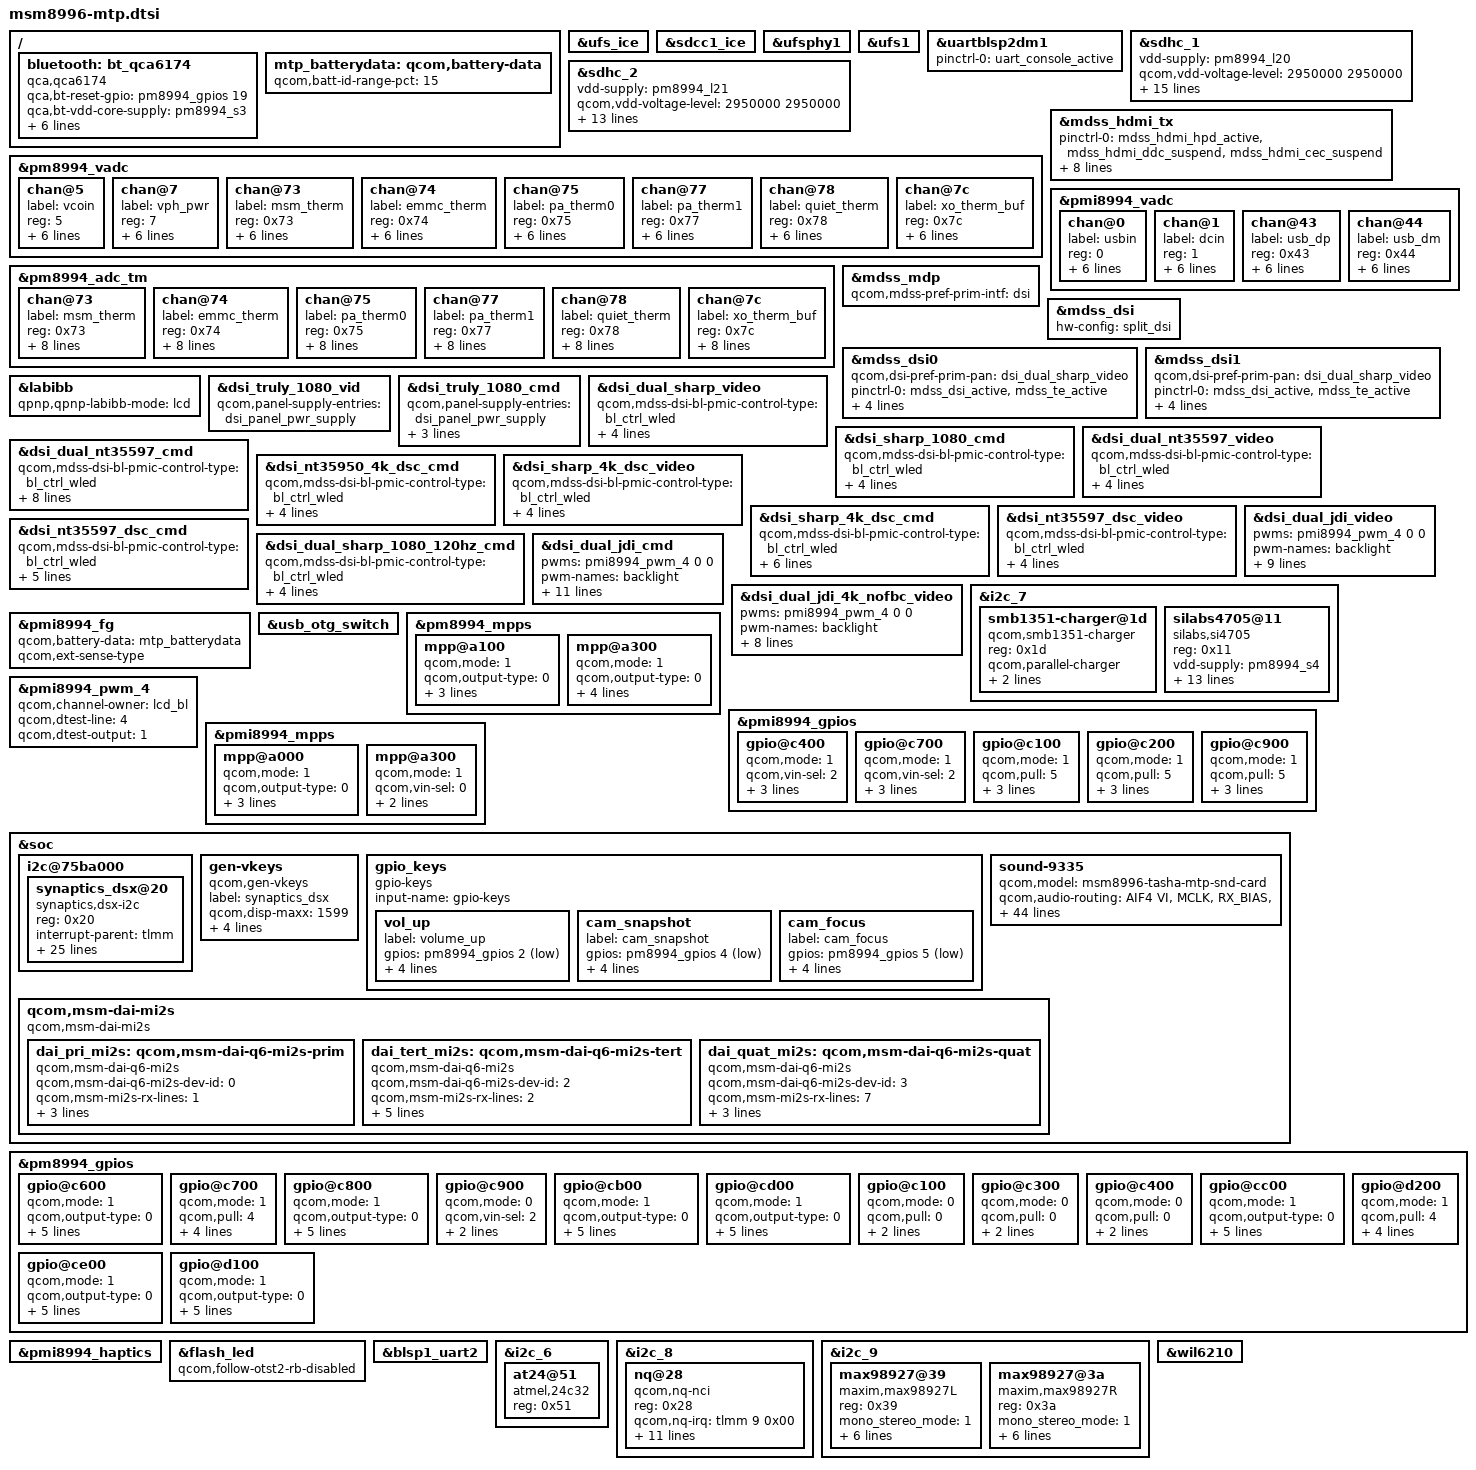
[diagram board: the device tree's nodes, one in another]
/* Copyright (c) 2015-2016, The Linux Foundation. All rights reserved.
 *
 * This program is free software; you can redistribute it and/or modify
 * it under the terms of the GNU General Public License version 2 and
 * only version 2 as published by the Free Software Foundation.
 *
 * This program is distributed in the hope that it will be useful,
 * but WITHOUT ANY WARRANTY; without even the implied warranty of
 * MERCHANTABILITY or FITNESS FOR A PARTICULAR PURPOSE.  See the
 * GNU General Public License for more details.
 */

#include "msm8996-pinctrl.dtsi"
#include "msm8996-camera-sensor-mtp.dtsi"
#include "msm8996-wsa881x.dtsi"

/ {
	bluetooth: bt_qca6174 {
		compatible = "qca,qca6174";
		qca,bt-reset-gpio = <&pm8994_gpios 19 0>; /* BT_EN */
		qca,bt-vdd-core-supply = <&pm8994_s3>;
		qca,bt-vdd-pa-supply = <&rome_vreg>;
		qca,bt-vdd-io-supply = <&pm8994_s4>;
		qca,bt-vdd-xtal-supply = <&pm8994_l30>;
		qca,bt-chip-pwd-voltage-level = <1300000 1300000>;
		qca,bt-vdd-io-voltage-level = <1800000 1800000>;
		qca,bt-vdd-xtal-voltage-level = <1800000 1800000>;
	};
};

&ufs_ice {
        status = "ok";
};

&sdcc1_ice {
        status = "ok";
};

&ufsphy1 {
	status = "ok";
};

&ufs1 {
	status = "ok";
};

&uartblsp2dm1 {
	status = "ok";
	pinctrl-names = "default";
	pinctrl-0 = <&uart_console_active>;
};

&sdhc_1 {
	vdd-supply = <&pm8994_l20>;
	qcom,vdd-voltage-level = <2950000 2950000>;
	qcom,vdd-current-level = <200 570000>;

	vdd-io-supply = <&pm8994_s4>;
	qcom,vdd-io-always-on;
	qcom,vdd-io-voltage-level = <1800000 1800000>;
	qcom,vdd-io-current-level = <110 325000>;

	pinctrl-names = "active", "sleep";
	pinctrl-0 = <&sdc1_clk_on &sdc1_cmd_on &sdc1_data_on &sdc1_rclk_on>;
	pinctrl-1 = <&sdc1_clk_off &sdc1_cmd_off &sdc1_data_off &sdc1_rclk_off>;

	qcom,clk-rates = <400000 20000000 25000000 50000000 96000000 192000000 384000000>;
	qcom,ice-clk-rates = <300000000 150000000>;
	qcom,nonremovable;
	qcom,bus-speed-mode = "HS400_1p8v", "HS200_1p8v", "DDR_1p8v";

	status = "ok";
};

&sdhc_2 {
	vdd-supply = <&pm8994_l21>;
	qcom,vdd-voltage-level = <2950000 2950000>;
	qcom,vdd-current-level = <200 800000>;

	vdd-io-supply = <&pm8994_l13>;
	qcom,vdd-io-voltage-level = <1800000 2950000>;
	qcom,vdd-io-current-level = <200 22000>;

	pinctrl-names = "active", "sleep";
	pinctrl-0 = <&sdc2_clk_on  &sdc2_cmd_on &sdc2_data_on &sdc2_cd_on>;
	pinctrl-1 = <&sdc2_clk_off &sdc2_cmd_off &sdc2_data_off &sdc2_cd_off>;

	qcom,clk-rates = <400000 20000000 25000000 50000000 100000000 200000000>;
	qcom,bus-speed-mode = "SDR12", "SDR25", "SDR50", "DDR50", "SDR104";

	cd-gpios = <&tlmm 95 0x1>;

	status = "ok";
};

&pm8994_vadc {
	chan@5 {
		label = "vcoin";
		reg = <5>;
		qcom,decimation = <0>;
		qcom,pre-div-channel-scaling = <1>;
		qcom,calibration-type = "absolute";
		qcom,scale-function = <0>;
		qcom,hw-settle-time = <0>;
		qcom,fast-avg-setup = <0>;
	};

	chan@7 {
		label = "vph_pwr";
		reg = <7>;
		qcom,decimation = <0>;
		qcom,pre-div-channel-scaling = <1>;
		qcom,calibration-type = "absolute";
		qcom,scale-function = <0>;
		qcom,hw-settle-time = <0>;
		qcom,fast-avg-setup = <0>;
	};

	chan@73 {
		label = "msm_therm";
		reg = <0x73>;
		qcom,decimation = <0>;
		qcom,pre-div-channel-scaling = <0>;
		qcom,calibration-type = "ratiometric";
		qcom,scale-function = <2>;
		qcom,hw-settle-time = <2>;
		qcom,fast-avg-setup = <0>;
	};

	chan@74 {
		label = "emmc_therm";
		reg = <0x74>;
		qcom,decimation = <0>;
		qcom,pre-div-channel-scaling = <0>;
		qcom,calibration-type = "ratiometric";
		qcom,scale-function = <2>;
		qcom,hw-settle-time = <2>;
		qcom,fast-avg-setup = <0>;
	};

	chan@75 {
		label = "pa_therm0";
		reg = <0x75>;
		qcom,decimation = <0>;
		qcom,pre-div-channel-scaling = <0>;
		qcom,calibration-type = "ratiometric";
		qcom,scale-function = <2>;
		qcom,hw-settle-time = <2>;
		qcom,fast-avg-setup = <0>;
	};

	chan@77 {
		label = "pa_therm1";
		reg = <0x77>;
		qcom,decimation = <0>;
		qcom,pre-div-channel-scaling = <0>;
		qcom,calibration-type = "ratiometric";
		qcom,scale-function = <2>;
		qcom,hw-settle-time = <2>;
		qcom,fast-avg-setup = <0>;
	};

	chan@78 {
		label = "quiet_therm";
		reg = <0x78>;
		qcom,decimation = <0>;
		qcom,pre-div-channel-scaling = <0>;
		qcom,calibration-type = "ratiometric";
		qcom,scale-function = <2>;
		qcom,hw-settle-time = <2>;
		qcom,fast-avg-setup = <0>;
	};

	chan@7c {
		label = "xo_therm_buf";
		reg = <0x7c>;
		qcom,decimation = <0>;
		qcom,pre-div-channel-scaling = <0>;
		qcom,calibration-type = "ratiometric";
		qcom,scale-function = <4>;
		qcom,hw-settle-time = <2>;
		qcom,fast-avg-setup = <0>;
	};

	chan@7c {
		label = "xo_therm_buf";
		reg = <0x7c>;
		qcom,decimation = <0>;
		qcom,pre-div-channel-scaling = <0>;
		qcom,calibration-type = "ratiometric";
		qcom,scale-function = <4>;
		qcom,hw-settle-time = <2>;
		qcom,fast-avg-setup = <0>;
	};
};

&pm8994_adc_tm {
	chan@73 {
		label = "msm_therm";
		reg = <0x73>;
		qcom,decimation = <0>;
		qcom,pre-div-channel-scaling = <0>;
		qcom,calibration-type = "ratiometric";
		qcom,scale-function = <2>;
		qcom,hw-settle-time = <2>;
		qcom,fast-avg-setup = <0>;
		qcom,btm-channel-number = <0x48>;
		qcom,thermal-node;
	};

	chan@74 {
		label = "emmc_therm";
		reg = <0x74>;
		qcom,decimation = <0>;
		qcom,pre-div-channel-scaling = <0>;
		qcom,calibration-type = "ratiometric";
		qcom,scale-function = <2>;
		qcom,hw-settle-time = <2>;
		qcom,fast-avg-setup = <0>;
		qcom,btm-channel-number = <0x68>;
		qcom,thermal-node;
	};

	chan@75 {
		label = "pa_therm0";
		reg = <0x75>;
		qcom,decimation = <0>;
		qcom,pre-div-channel-scaling = <0>;
		qcom,calibration-type = "ratiometric";
		qcom,scale-function = <2>;
		qcom,hw-settle-time = <2>;
		qcom,fast-avg-setup = <0>;
		qcom,btm-channel-number = <0x70>;
		qcom,thermal-node;
	};

	chan@77 {
		label = "pa_therm1";
		reg = <0x77>;
		qcom,decimation = <0>;
		qcom,pre-div-channel-scaling = <0>;
		qcom,calibration-type = "ratiometric";
		qcom,scale-function = <2>;
		qcom,hw-settle-time = <2>;
		qcom,fast-avg-setup = <0>;
		qcom,btm-channel-number = <0x78>;
		qcom,thermal-node;
	};

	chan@78 {
		label = "quiet_therm";
		reg = <0x78>;
		qcom,decimation = <0>;
		qcom,pre-div-channel-scaling = <0>;
		qcom,calibration-type = "ratiometric";
		qcom,scale-function = <2>;
		qcom,hw-settle-time = <2>;
		qcom,fast-avg-setup = <0>;
		qcom,btm-channel-number = <0x80>;
		qcom,thermal-node;
	};

	chan@7c {
		label = "xo_therm_buf";
		reg = <0x7c>;
		qcom,decimation = <0>;
		qcom,pre-div-channel-scaling = <0>;
		qcom,calibration-type = "ratiometric";
		qcom,scale-function = <4>;
		qcom,hw-settle-time = <2>;
		qcom,fast-avg-setup = <0>;
		qcom,btm-channel-number = <0x88>;
		qcom,thermal-node;
	};
};

&mdss_hdmi_tx {
	pinctrl-names = "hdmi_hpd_active", "hdmi_ddc_active", "hdmi_cec_active",
				"hdmi_active", "hdmi_sleep";
	pinctrl-0 = <&mdss_hdmi_hpd_active &mdss_hdmi_ddc_suspend
						&mdss_hdmi_cec_suspend>;
	pinctrl-1 = <&mdss_hdmi_hpd_active &mdss_hdmi_ddc_active
						&mdss_hdmi_cec_suspend>;
	pinctrl-2 = <&mdss_hdmi_hpd_active &mdss_hdmi_cec_active
						&mdss_hdmi_ddc_suspend>;
	pinctrl-3 = <&mdss_hdmi_hpd_active &mdss_hdmi_ddc_active
						&mdss_hdmi_cec_active>;
	pinctrl-4 = <&mdss_hdmi_hpd_suspend &mdss_hdmi_ddc_suspend
						&mdss_hdmi_cec_suspend>;
};

&pmi8994_vadc {
	chan@0 {
		label = "usbin";
		reg = <0>;
		qcom,decimation = <0>;
		qcom,pre-div-channel-scaling = <4>;
		qcom,calibration-type = "absolute";
		qcom,scale-function = <0>;
		qcom,hw-settle-time = <0>;
		qcom,fast-avg-setup = <0>;
	};

	chan@1 {
		label = "dcin";
		reg = <1>;
		qcom,decimation = <0>;
		qcom,pre-div-channel-scaling = <4>;
		qcom,calibration-type = "absolute";
		qcom,scale-function = <0>;
		qcom,hw-settle-time = <0>;
		qcom,fast-avg-setup = <0>;
	};

	chan@43 {
		label = "usb_dp";
		reg = <0x43>;
		qcom,decimation = <0>;
		qcom,pre-div-channel-scaling = <1>;
		qcom,calibration-type = "absolute";
		qcom,scale-function = <0>;
		qcom,hw-settle-time = <0>;
		qcom,fast-avg-setup = <0>;
	};

	chan@44 {
		label = "usb_dm";
		reg = <0x44>;
		qcom,decimation = <0>;
		qcom,pre-div-channel-scaling = <1>;
		qcom,calibration-type = "absolute";
		qcom,scale-function = <0>;
		qcom,hw-settle-time = <0>;
		qcom,fast-avg-setup = <0>;
	};
};

#include "msm8996-mdss-panels.dtsi"

&mdss_mdp {
	qcom,mdss-pref-prim-intf = "dsi";
};

&mdss_dsi {
	hw-config = "split_dsi";
};

&mdss_dsi0 {
	qcom,dsi-pref-prim-pan = <&dsi_dual_sharp_video>;
	pinctrl-names = "mdss_default", "mdss_sleep";
	pinctrl-0 = <&mdss_dsi_active &mdss_te_active>;
	pinctrl-1 = <&mdss_dsi_suspend &mdss_te_suspend>;
	qcom,platform-te-gpio = <&tlmm 10 0>;
	qcom,platform-reset-gpio = <&tlmm 8 0>;
	qcom,platform-bklight-en-gpio = <&pm8994_gpios 14 0>;
};

&mdss_dsi1 {
	qcom,dsi-pref-prim-pan = <&dsi_dual_sharp_video>;
	pinctrl-names = "mdss_default", "mdss_sleep";
	pinctrl-0 = <&mdss_dsi_active &mdss_te_active>;
	pinctrl-1 = <&mdss_dsi_suspend &mdss_te_suspend>;
	qcom,platform-te-gpio = <&tlmm 10 0>;
	qcom,platform-reset-gpio = <&tlmm 8 0>;
	qcom,platform-bklight-en-gpio = <&pm8994_gpios 14 0>;
};

&labibb {
	status = "ok";
	qpnp,qpnp-labibb-mode = "lcd";
};

&dsi_truly_1080_vid {
	qcom,panel-supply-entries = <&dsi_panel_pwr_supply>;
};

&dsi_truly_1080_cmd {
	qcom,panel-supply-entries = <&dsi_panel_pwr_supply>;
	qcom,ulps-enabled;
	qcom,partial-update-enabled;
	qcom,panel-roi-alignment = <2 2 4 2 1080 2>;
};

&dsi_dual_sharp_video {
	qcom,mdss-dsi-bl-pmic-control-type = "bl_ctrl_wled";
	qcom,mdss-dsi-bl-min-level = <1>;
	qcom,mdss-dsi-bl-max-level = <4095>;
	qcom,panel-supply-entries = <&dsi_panel_pwr_supply>;
};

&dsi_sharp_1080_cmd {
	qcom,mdss-dsi-bl-pmic-control-type = "bl_ctrl_wled";
	qcom,mdss-dsi-bl-min-level = <1>;
	qcom,mdss-dsi-bl-max-level = <4095>;
	qcom,panel-supply-entries = <&dsi_panel_pwr_supply>;
};

&dsi_dual_nt35597_video {
	qcom,mdss-dsi-bl-pmic-control-type = "bl_ctrl_wled";
	qcom,mdss-dsi-bl-min-level = <1>;
	qcom,mdss-dsi-bl-max-level = <4095>;
	qcom,panel-supply-entries = <&dsi_panel_pwr_supply>;
};

&dsi_dual_nt35597_cmd {
	qcom,mdss-dsi-bl-pmic-control-type = "bl_ctrl_wled";
	qcom,mdss-dsi-bl-min-level = <1>;
	qcom,mdss-dsi-bl-max-level = <4095>;
	qcom,panel-supply-entries = <&dsi_panel_pwr_supply>;
	qcom,partial-update-enabled;
	qcom,panel-roi-alignment = <720 128 720 64 720 64>;
	qcom,panel-allow-phy-poweroff;
};

&dsi_nt35950_4k_dsc_cmd {
	qcom,mdss-dsi-bl-pmic-control-type = "bl_ctrl_wled";
	qcom,mdss-dsi-bl-min-level = <1>;
	qcom,mdss-dsi-bl-max-level = <4095>;
	qcom,panel-supply-entries = <&dsi_panel_pwr_supply>;
};

&dsi_sharp_4k_dsc_video {
	qcom,mdss-dsi-bl-pmic-control-type = "bl_ctrl_wled";
	qcom,mdss-dsi-bl-min-level = <1>;
	qcom,mdss-dsi-bl-max-level = <4095>;
	qcom,panel-supply-entries = <&dsi_panel_pwr_supply>;
};

&dsi_sharp_4k_dsc_cmd {
	qcom,mdss-dsi-bl-pmic-control-type = "bl_ctrl_wled";
	qcom,mdss-dsi-bl-min-level = <1>;
	qcom,mdss-dsi-bl-max-level = <4095>;
	qcom,panel-supply-entries = <&dsi_panel_pwr_supply>;
	qcom,partial-update-enabled;
	/* panel supports slice height of 8/16/32/48/3840 */
	qcom,panel-roi-alignment = <1080 8 1080 8 1080 8>;
};

&dsi_nt35597_dsc_video {
	qcom,mdss-dsi-bl-pmic-control-type = "bl_ctrl_wled";
	qcom,mdss-dsi-bl-min-level = <1>;
	qcom,mdss-dsi-bl-max-level = <4095>;
	qcom,panel-supply-entries = <&dsi_panel_pwr_supply>;
};

&dsi_nt35597_dsc_cmd {
	qcom,mdss-dsi-bl-pmic-control-type = "bl_ctrl_wled";
	qcom,mdss-dsi-bl-min-level = <1>;
	qcom,mdss-dsi-bl-max-level = <4095>;
	qcom,panel-supply-entries = <&dsi_panel_pwr_supply>;
	qcom,panel-allow-phy-poweroff;
};

&dsi_dual_sharp_1080_120hz_cmd {
	qcom,mdss-dsi-bl-pmic-control-type = "bl_ctrl_wled";
	qcom,mdss-dsi-bl-min-level = <1>;
	qcom,mdss-dsi-bl-max-level = <4095>;
	qcom,panel-supply-entries = <&dsi_panel_pwr_supply>;
};

&dsi_dual_jdi_video {
	pwms = <&pmi8994_pwm_4 0 0>;
	pwm-names = "backlight";
	qcom,mdss-dsi-bl-pmic-control-type = "bl_ctrl_pwm";
	qcom,mdss-dsi-bl-pwm-pmi;
	qcom,mdss-dsi-bl-pmic-pwm-frequency = <100>;
	qcom,mdss-dsi-bl-min-level = <1>;
	qcom,mdss-dsi-bl-max-level = <4095>;
	qcom,5v-boost-gpio = <&pmi8994_gpios 8 0>;
	qcom,panel-supply-entries = <&dsi_panel_pwr_supply>;
};

&dsi_dual_jdi_cmd {
	pwms = <&pmi8994_pwm_4 0 0>;
	pwm-names = "backlight";
	qcom,mdss-dsi-bl-pmic-control-type = "bl_ctrl_pwm";
	qcom,mdss-dsi-bl-pwm-pmi;
	qcom,mdss-dsi-bl-pmic-pwm-frequency = <100>;
	qcom,mdss-dsi-bl-min-level = <1>;
	qcom,mdss-dsi-bl-max-level = <4095>;
	qcom,5v-boost-gpio = <&pmi8994_gpios 8 0>;
	qcom,panel-supply-entries = <&dsi_panel_pwr_supply>;
	qcom,partial-update-enabled;
	qcom,panel-roi-alignment = <4 4 2 2 20 20>;
};

&dsi_dual_jdi_4k_nofbc_video {
	pwms = <&pmi8994_pwm_4 0 0>;
	pwm-names = "backlight";
	qcom,mdss-dsi-bl-pmic-control-type = "bl_ctrl_pwm";
	qcom,mdss-dsi-bl-pwm-pmi;
	qcom,mdss-dsi-bl-pmic-pwm-frequency = <100>;
	qcom,mdss-dsi-bl-min-level = <1>;
	qcom,mdss-dsi-bl-max-level = <4095>;
	qcom,panel-supply-entries = <&dsi_panel_pwr_supply>;
};

/{
	mtp_batterydata: qcom,battery-data {
		qcom,batt-id-range-pct = <15>;
		#include "batterydata-zl1-4000mah.dtsi"
	};
};

&i2c_7 {
	smb1351-charger@1d {
		compatible = "qcom,smb1351-charger";
		reg = <0x1d>;
		qcom,parallel-charger;
		qcom,float-voltage-mv = <4400>;
		qcom,recharge-mv = <100>;
	};
};

&pmi8994_fg {
	qcom,battery-data = <&mtp_batterydata>;
	qcom,ext-sense-type;
};

&usb_otg_switch {
	status = "okay";
};

&pm8994_mpps {
	mpp@a100 { /* MPP 2 */
		qcom,mode = <1>;		/* Digital output */
		qcom,output-type = <0>;		/* CMOS logic */
		qcom,vin-sel = <2>;		/* S4 1.8V */
		qcom,src-sel = <0>;		/* Constant */
		qcom,master-en = <1>;		/* Enable GPIO */
		status = "okay";
	};

	mpp@a300 { /* MPP 4 */
		/* HDMI_5v_vreg regulator enable */
		qcom,mode = <1>;		/* Digital output */
		qcom,output-type = <0>;		/* CMOS logic */
		qcom,vin-sel = <2>;		/* S4 1.8V */
		qcom,src-sel = <0>;		/* Constant */
		qcom,master-en = <1>;		/* Enable GPIO */
		qcom,invert = <1>;
		status = "okay";
	};
};

&pmi8994_gpios {
	gpio@c400 { /* GPIO 5 - USB3 OTG SWITCH EN */
		qcom,mode = <1>;	/* Digital output */
		qcom,vin-sel = <2>;	/* 1.8 */
		qcom,src-sel = <0>;	/* GPIO */
		qcom,master-en = <1>;	/* Enable GPIO */
		qcom,invert = <0>;	/* Output low initially */
		status = "okay";
	};
};

&pmi8994_gpios {
	gpio@c700 {	/* GPIO 8, lcd_reg_en, 5V boost  */
		qcom,mode = <1>;
		qcom,vin-sel = <2>;
		qcom,src-sel = <0>;
		qcom,invert = <1>;   /* need invert = 0 */
		qcom,master-en = <1>;
		status = "okay";
	};

	gpio@c100 {	/* GPIO 2  SPKR_SD_N */
		qcom,mode = <1>;	/* DIGITAL OUT */
		qcom,pull = <5>;	/* No Pull */
		qcom,vin-sel = <2>;	/* 1.8 */
		qcom,src-sel = <0>;	/* CONSTANT */
		qcom,master-en = <1>;	/* ENABLE GPIO */
		status = "okay";
	};

	gpio@c200 {	/* GPIO 3 SPKR_SD_N */
		qcom,mode = <1>;	/* DIGITAL OUT */
		qcom,pull = <5>;	/* No Pull */
		qcom,vin-sel = <2>;	/* 1.8 */
		qcom,src-sel = <0>;	/* CONSTANT */
		qcom,master-en = <1>;	/* ENABLE GPIO */
		status = "okay";
	};

	gpio@c900 { /* GPIO 10 - HPH_EN1 */
		qcom,mode = <1>;
		qcom,pull = <5>;
		qcom,vin-sel = <2>;
		qcom,src-sel = <2>;
		qcom,master-en = <1>;
		status = "okay";
	};
};

&pmi8994_pwm_4 {
	qcom,channel-owner = "lcd_bl";
	qcom,dtest-line = <4>;
	qcom,dtest-output = <1>;
	status = "okay";
};

&pmi8994_mpps {
	mpp@a000 { /* MPP 1 */
		qcom,mode = <1>;                /* Digital output */
		qcom,output-type = <0>;         /* CMOS logic */
		qcom,vin-sel = <2>;             /* S4 1.8V */
		qcom,src-sel = <7>;             /* DTEST4 */
		qcom,master-en = <1>;           /* Enable MPP */
		status = "okay";
	};

	mpp@a300 { /* MPP 4 */
		/* WLED FET */
		qcom,mode = <1>;        /* DIGITAL OUT */
		qcom,vin-sel = <0>;     /* VIN0 */
		qcom,src-sel = <1>;
		qcom,master-en = <1>;
		status = "okay";
	};
};

&soc {
	i2c@75ba000 {
		#address-cells = <1>;
		#size-cells = <0>;
		synaptics_dsx@20 {
			compatible = "synaptics,dsx-i2c";
			reg = <0x20>;
			interrupt-parent = <&tlmm>;
			interrupts = <125 0x2008>;
			pinctrl-names = "pmx_ts_active","pmx_ts_suspend";
			pinctrl-0 = <&synaptics_irq_active &synaptics_reset_active>;
			pinctrl-1 = <&synaptics_irq_suspend &synaptics_reset_suspend>;
			vdd_ana-supply = <&pm8994_l22>;
			vcc_i2c-supply = <&pm8994_l14>;
			synaptics,pwr-reg-name = "vdd_ana";
			synaptics,bus-reg-name = "vcc_i2c";
			synaptics,reset-gpio = <&tlmm 89 0x00>;
			synaptics,irq-gpio = <&tlmm 125 0x2008>;
			synaptics,irq-on-state = <0>;
			synaptics,irq-flags = <0x2008>; /* IRQF_ONESHOT | IRQF_TRIGGER_LOW */
			synaptics,power-delay-ms = <200>;
			synaptics,reset-delay-ms = <200>;
			synaptics,reset-on-state = <0>;
			synaptics,reset-active-ms = <20>;
			synaptics,disable-gpios;
			/* Underlying clocks used by secure touch */
			synaptics,cap-button-codes = <580 172 158>;
			synaptics,driver-line-num = <31>;
			synaptics,sense-line-num = <20>;
			synaptics,capacitance-max-value = <
                            2987  2828  2789  2817  2863  2624  2612  2601  2589  2606  2592  2582  2616  2933  2873  2884  3039  0     0     0
                            2960  2805  2766  2793  2838  2600  2589  2577  2567  2583  2568  2558  2591  2909  2850  2861  3012  0     0     0
                            2965  2811  2772  2799  2845  2606  2594  2584  2573  2590  2575  2565  2598  2915  2857  2868  3018  0     0     0
                            2970  2814  2776  2804  2849  2610  2600  2589  2578  2595  2580  2570  2602  2920  2859  2872  3021  0     0     0
                            2975  2818  2779  2808  2854  2615  2603  2594  2582  2599  2584  2574  2608  2925  2865  2876  3025  0     0     0
                            2981  2826  2788  2815  2862  2623  2612  2602  2592  2608  2593  2584  2617  2933  2874  2884  3033  0     0     0
                            2984  2829  2791  2820  2867  2628  2617  2608  2597  2613  2599  2588  2621  2937  2878  2888  3037  0     0     0
                            2990  2836  2798  2827  2874  2634  2624  2614  2605  2620  2606  2597  2630  2945  2885  2895  3044  0     0     0
                            2996  2842  2805  2834  2882  2644  2633  2623  2614  2629  2615  2605  2637  2951  2891  2901  3049  0     0     0
                            3002  2850  2812  2842  2890  2650  2639  2628  2620  2636  2621  2612  2644  2958  2897  2905  3054  0     0     0
                            3010  2857  2819  2849  2899  2657  2648  2638  2628  2643  2629  2620  2651  2964  2902  2913  3059  0     0     0
                            3018  2865  2828  2859  2910  2668  2657  2648  2638  2653  2640  2631  2663  2974  2912  2921  3065  0     0     0
                            3024  2872  2835  2866  2917  2675  2667  2657  2647  2661  2648  2639  2672  2981  2919  2928  3071  0     0     0
                            3034  2881  2845  2876  2928  2686  2676  2668  2660  2674  2659  2651  2683  2991  2928  2936  3078  0     0     0
                            3040  2889  2853  2886  2939  2696  2687  2678  2670  2683  2670  2662  2694  3001  2936  2945  3085  0     0     0
                            3045  2896  2861  2894  2948  2703  2693  2687  2678  2690  2678  2670  2703  3007  2943  2951  3091  0     0     0
                            3052  2904  2869  2903  2958  2712  2703  2697  2688  2702  2686  2679  2713  3016  2951  2959  3097  0     0     0
                            3058  2913  2877  2912  2968  2723  2714  2707  2699  2712  2697  2691  2724  3025  2960  2968  3104  0     0     0
                            3062  2918  2884  2919  2976  2731  2721  2716  2707  2720  2706  2700  2733  3032  2967  2974  3109  0     0     0
                            3071  2928  2896  2931  2989  2742  2734  2729  2721  2732  2720  2714  2746  3043  2978  2984  3118  0     0     0
                            3076  2936  2903  2940  3000  2752  2744  2739  2731  2742  2730  2724  2756  3053  2986  2991  3123  0     0     0
                            3083  2944  2912  2949  3011  2761  2754  2749  2743  2754  2742  2736  2767  3063  2995  3000  3129  0     0     0
                            3087  2949  2918  2955  3018  2769  2760  2757  2749  2760  2748  2744  2775  3068  3001  3006  3134  0     0     0
                            3092  2956  2925  2963  3026  2777  2768  2766  2759  2769  2757  2754  2785  3075  3008  3012  3139  0     0     0
                            3097  2963  2932  2972  3037  2785  2777  2775  2768  2777  2766  2763  2795  3082  3015  3019  3144  0     0     0
                            3103  2971  2943  2982  3048  2794  2787  2786  2779  2787  2777  2774  2806  3090  3023  3028  3150  0     0     0
                            3107  2977  2949  2989  3056  2803  2795  2794  2787  2795  2785  2783  2815  3096  3029  3032  3154  0     0     0
                            3111  2986  2959  2998  3064  2814  2806  2804  2798  2806  2796  2794  2825  3103  3038  3041  3159  0     0     0
                            3120  2996  2970  3010  3077  2827  2819  2819  2814  2821  2810  2807  2839  3113  3049  3051  3168  0     0     0
                            3201  3102  3065  3104  3168  2926  2919  3006  3101  3062  2968  2920  2950  3212  3174  3186  3255  0     0     0
                            0     0     0     0     0     0     0     0     0     0     0     0     0     0     0     0     0     3217  3243  3438>;
			synaptics,capacitance-min-value = <
		                    1992  1886  1859  1878  1909  1749  1741  1734  1726  1737  1728  1721  1744  1955  1915  1923  2026  0     0     0
		                    1974  1870  1844  1862  1892  1733  1726  1718  1711  1722  1712  1705  1727  1939  1900  1907  2008  0     0     0
		                    1977  1874  1848  1866  1897  1737  1729  1723  1715  1726  1717  1710  1732  1944  1905  1912  2012  0     0     0
		                    1980  1876  1851  1869  1900  1740  1733  1726  1719  1730  1720  1713  1734  1947  1906  1915  2014  0     0     0
		                    1983  1879  1853  1872  1902  1743  1735  1729  1722  1733  1723  1716  1739  1950  1910  1917  2017  0     0     0
		                    1988  1884  1858  1877  1908  1749  1741  1735  1728  1739  1729  1722  1744  1955  1916  1923  2022  0     0     0
		                    1989  1886  1860  1880  1911  1752  1745  1738  1731  1742  1732  1725  1748  1958  1918  1925  2025  0     0     0
		                    1993  1891  1865  1885  1916  1756  1749  1743  1736  1747  1737  1731  1753  1963  1923  1930  2029  0     0     0
		                    1997  1895  1870  1889  1921  1762  1755  1749  1743  1753  1743  1737  1758  1968  1927  1934  2033  0     0     0
		                    2002  1900  1874  1894  1926  1767  1759  1752  1747  1757  1748  1741  1763  1972  1931  1937  2036  0     0     0
		                    2007  1905  1879  1899  1933  1772  1765  1758  1752  1762  1753  1747  1768  1976  1935  1942  2039  0     0     0
		                    2012  1910  1886  1906  1940  1779  1771  1766  1759  1769  1760  1754  1775  1983  1941  1947  2044  0     0     0
		                    2016  1914  1890  1911  1944  1783  1778  1771  1765  1774  1766  1760  1781  1987  1946  1952  2047  0     0     0
		                    2022  1921  1896  1918  1952  1791  1784  1779  1773  1782  1773  1767  1789  1994  1952  1958  2052  0     0     0
		                    2026  1926  1902  1924  1960  1797  1791  1786  1780  1789  1780  1775  1796  2001  1958  1963  2057  0     0     0
		                    2030  1931  1907  1930  1965  1802  1795  1791  1785  1794  1785  1780  1802  2005  1962  1968  2060  0     0     0
		                    2035  1936  1912  1935  1972  1808  1802  1798  1792  1801  1791  1786  1809  2011  1968  1973  2065  0     0     0
		                    2038  1942  1918  1942  1979  1815  1809  1805  1799  1808  1798  1794  1816  2017  1973  1979  2069  0     0     0
		                    2042  1945  1923  1946  1984  1821  1814  1810  1805  1813  1804  1800  1822  2021  1978  1982  2073  0     0     0
		                    2047  1952  1931  1954  1993  1828  1823  1819  1814  1822  1813  1809  1831  2029  1985  1989  2078  0     0     0
		                    2051  1957  1935  1960  2000  1835  1829  1826  1820  1828  1820  1816  1837  2035  1991  1994  2082  0     0     0
		                    2055  1962  1942  1966  2007  1841  1836  1833  1828  1836  1828  1824  1845  2042  1997  2000  2086  0     0     0
		                    2058  1966  1945  1970  2012  1846  1840  1838  1833  1840  1832  1829  1850  2045  2001  2004  2090  0     0     0
		                    2061  1971  1950  1975  2017  1851  1845  1844  1839  1846  1838  1836  1857  2050  2006  2008  2093  0     0     0
		                    2064  1975  1955  1981  2025  1857  1851  1850  1845  1852  1844  1842  1863  2054  2010  2013  2096  0     0     0
		                    2068  1981  1962  1988  2032  1863  1858  1857  1853  1858  1851  1850  1871  2060  2016  2018  2100  0     0     0
		                    2071  1985  1966  1993  2037  1869  1864  1863  1858  1864  1857  1855  1876  2064  2020  2022  2102  0     0     0
		                    2074  1990  1972  1999  2042  1876  1871  1869  1866  1871  1864  1862  1883  2069  2025  2027  2106  0     0     0
		                    2080  1998  1980  2006  2051  1884  1879  1879  1876  1880  1873  1871  1893  2076  2033  2034  2112  0     0     0
		                    2134  2068  2043  2069  2112  1951  1946  2004  2067  2042  1979  1947  1967  2141  2116  2124  2170  0     0     0
		                    0     0     0     0     0     0     0     0     0     0     0     0     0     0     0     0     0     1920  1940  2060>;
		};
	};

	gen-vkeys {
		compatible = "qcom,gen-vkeys";
		label = "synaptics_dsx";
		qcom,disp-maxx = <1599>;
		qcom,disp-maxy = <2559>;
		qcom,panel-maxx = <1599>;
		qcom,panel-maxy = <2703>;
		qcom,key-codes = <158 139 102 217>;
	};

	gpio_keys {
		compatible = "gpio-keys";
		input-name = "gpio-keys";

		vol_up {
			label = "volume_up";
			gpios = <&pm8994_gpios 2 0x1>;
			linux,input-type = <1>;
			linux,code = <115>;
			gpio-key,wakeup;
			debounce-interval = <15>;
		};

		cam_snapshot {
			label = "cam_snapshot";
			gpios = <&pm8994_gpios 4 0x1>;
			linux,input-type = <1>;
			linux,code = <766>;
			gpio-key,wakeup;
			debounce-interval = <15>;
		};

		cam_focus {
			label = "cam_focus";
			gpios = <&pm8994_gpios 5 0x1>;
			linux,input-type = <1>;
			linux,code = <528>;
			gpio-key,wakeup;
			debounce-interval = <15>;
		};
	};

	sound-9335 {
		qcom,model = "msm8996-tasha-mtp-snd-card";

		qcom,audio-routing =
			"AIF4 VI", "MCLK",
			"RX_BIAS", "MCLK",
			"MADINPUT", "MCLK",
			"AMIC2", "MIC BIAS2",
			"MIC BIAS2", "Headset Mic",
			"AMIC1", "MIC BIAS1",
			"MIC BIAS1", "Handset Mic",
			"AMIC4", "MIC BIAS4",
			"MIC BIAS4", "REC ANC Analog Mic",
			"AMIC5", "MIC BIAS3",
			"MIC BIAS3", "ANC Analog Mic";

		asoc-platform = <&pcm0>, <&pcm1>, <&pcm2>, <&voip>, <&voice>,
				<&loopback>, <&compress>, <&hostless>,
				<&afe>, <&lsm>, <&routing>, <&cpe>, <&compr>;
		asoc-platform-names = "msm-pcm-dsp.0", "msm-pcm-dsp.1", "msm-pcm-dsp.2",
				"msm-voip-dsp", "msm-pcm-voice", "msm-pcm-loopback",
				"msm-compress-dsp", "msm-pcm-hostless", "msm-pcm-afe",
				"msm-lsm-client", "msm-pcm-routing", "msm-cpe-lsm",
				"msm-compr-dsp";
		asoc-cpu = <&dai_pri_auxpcm>, <&dai_sec_auxpcm>, <&dai_hdmi>,
				<&dai_pri_mi2s>,
				<&dai_tert_mi2s>, <&dai_quat_mi2s>,
				<&sb_0_rx>, <&sb_0_tx>, <&sb_1_rx>, <&sb_1_tx>,
				<&sb_2_rx>, <&sb_2_tx>, <&sb_3_rx>, <&sb_3_tx>,
				<&sb_4_rx>, <&sb_4_tx>, <&sb_5_tx>, <&afe_pcm_rx>,
				<&afe_pcm_tx>, <&afe_proxy_rx>, <&afe_proxy_tx>,
				<&incall_record_rx>, <&incall_record_tx>,
				<&incall_music_rx>, <&incall_music2_rx>,
				<&sb_5_rx>, <&sb_6_rx>;
		asoc-cpu-names = "msm-dai-q6-auxpcm.1", "msm-dai-q6-auxpcm.2",
				"msm-dai-q6-hdmi.8",
				"msm-dai-q6-mi2s.0",
				"msm-dai-q6-mi2s.2", "msm-dai-q6-mi2s.3",
				"msm-dai-q6-dev.16384", "msm-dai-q6-dev.16385",
				"msm-dai-q6-dev.16386", "msm-dai-q6-dev.16387",
				"msm-dai-q6-dev.16388", "msm-dai-q6-dev.16389",
				"msm-dai-q6-dev.16390", "msm-dai-q6-dev.16391",
				"msm-dai-q6-dev.16392", "msm-dai-q6-dev.16393",
				"msm-dai-q6-dev.16395", "msm-dai-q6-dev.224",
				"msm-dai-q6-dev.225", "msm-dai-q6-dev.241",
				"msm-dai-q6-dev.240", "msm-dai-q6-dev.32771",
				"msm-dai-q6-dev.32772", "msm-dai-q6-dev.32773",
				"msm-dai-q6-dev.32770", "msm-dai-q6-dev.16394",
                "msm-dai-q6-dev.16396";

		qcom,hdmi-audio-rx;
		/*letv,hifi-audio;*/
		/*letv,smartpa-audio;*/
		letv,smartpa-audio-max98927;
		letv,hph_irq_detect = <0>;
		asoc-codec = <&stub_codec>, <&hdmi_audio>;
		asoc-codec-names = "msm-stub-codec.1", "msm-hdmi-audio-codec-rx";
		/delete-property/ qcom,hph-en1-gpio;
		/delete-property/ qcom,hph-en0-gpio;
		qcom,us-euro-gpios = <&tlmm 21 0>;
		/delete-property/ qcom,wsa-devs;
		/delete-property/ qcom,wsa-aux-dev-prefix;
	};

	qcom,msm-dai-mi2s {
		compatible = "qcom,msm-dai-mi2s";
		dai_pri_mi2s: qcom,msm-dai-q6-mi2s-prim {
			compatible = "qcom,msm-dai-q6-mi2s";
			qcom,msm-dai-q6-mi2s-dev-id = <0>;
			qcom,msm-mi2s-rx-lines = <1>; /* SD0 (1 << 0) */
			qcom,msm-mi2s-tx-lines = <2>; /* SD1 (1 << 1) */
			qcom,msm-mi2s-slave = <0>;
			qcom,msm-mi2s-ext-mclk = <0>;
		};
	};

	qcom,msm-dai-mi2s {
		compatible = "qcom,msm-dai-mi2s";
		dai_tert_mi2s: qcom,msm-dai-q6-mi2s-tert {
			compatible = "qcom,msm-dai-q6-mi2s";
			qcom,msm-dai-q6-mi2s-dev-id = <2>;
			qcom,msm-mi2s-rx-lines = <2>;
			qcom,msm-mi2s-tx-lines = <1>;
			pinctrl-names = "default", "sleep";
			pinctrl-0 = <&tert_mi2s_active &tert_mi2s_sd0_active &tert_mi2s_sd1_active>;
			pinctrl-1 = <&tert_mi2s_sleep &tert_mi2s_sd0_sleep &tert_mi2s_sd1_sleep>;
		};
	};

	qcom,msm-dai-mi2s {
		compatible = "qcom,msm-dai-mi2s";
		dai_quat_mi2s: qcom,msm-dai-q6-mi2s-quat {
			compatible = "qcom,msm-dai-q6-mi2s";
			qcom,msm-dai-q6-mi2s-dev-id = <3>;
			qcom,msm-mi2s-rx-lines = <7>; /* SD0 (1 << 0) | SD1 (1 << 1) | SD2 (1 << 2) */
			qcom,msm-mi2s-tx-lines = <8>; /* SD2 (1 << 3) */
			qcom,msm-mi2s-slave = <0>;
			qcom,msm-mi2s-ext-mclk = <12288000>;
		};
	};
};

&pm8994_gpios {
	gpio@c600 { /* GPIO 7 - NFC DWL REQ */
		qcom,mode = <1>;
		qcom,output-type = <0>;
		qcom,pull = <5>;
		qcom,vin-sel = <2>;
		qcom,out-strength = <3>;
		qcom,src-sel = <0>;
		qcom,master-en = <1>;
		status = "okay";
	};

	gpio@c700 { /* GPIO 8 - WLAN_EN */
		qcom,mode = <1>;		/* Digital output*/
		qcom,pull = <4>;		/* Pulldown 10uA */
		qcom,vin-sel = <2>;		/* VIN2 */
		qcom,src-sel = <0>;		/* GPIO */
		qcom,invert = <0>;		/* Invert */
		qcom,master-en = <1>;		/* Enable GPIO */
		status = "okay";
	};

	gpio@c800 { /* GPIO 9 - Rome 3.3V control */
		qcom,mode = <1>;		/* Digital output */
		qcom,output-type = <0>;		/* MOS logic */
		qcom,invert = <1>;		/* Output high */
		qcom,vin-sel = <0>;		/* VPH_PWR */
		qcom,src-sel = <0>;		/* Constant */
		qcom,out-strength = <1>;	/* High drive strength */
		qcom,master-en = <1>;		/* Enable GPIO */
		status = "okay";
	};

	gpio@c900 { /* GPIO 10 - NFC CLK _REQ*/
		qcom,mode = <0>;
		qcom,vin-sel = <2>;
		qcom,src-sel = <0>;
		qcom,master-en = <1>;
		status = "okay";
	};

	gpio@cb00 { /* GPIO 12 - NFC ESE PWR REQ */
		qcom,mode = <1>;
		qcom,output-type = <0>;
		qcom,pull = <5>;
		qcom,vin-sel = <2>;
		qcom,out-strength = <3>;
		qcom,src-sel = <0>;
		qcom,master-en = <1>;
		status = "okay";
	};

	gpio@cd00 { /* GPIO 14 - lcd_bklt_reg_en */
		qcom,mode = <1>;	/* DIGITAL OUT */
		qcom,output-type = <0>;		/* CMOS logic */
		qcom,invert = <1>; 	/* output hight initially */
		qcom,vin-sel = <2>;	/* 1.8 */
		qcom,src-sel = <0>;	/* CONSTANT */
		qcom,out-strength = <1>;	/* Low drive strength */
		qcom,master-en = <1>;	/* ENABLE GPIO */
		status = "okay";
	};
	gpio@c100 { /* GPIO 2 */
		qcom,mode = <0>;
		qcom,pull = <0>;
		qcom,vin-sel = <2>;
		qcom,src-sel = <0>;
		status = "okay";
	};

	gpio@c300 { /* GPIO 4 */
		qcom,mode = <0>;
		qcom,pull = <0>;
		qcom,vin-sel = <2>;
		qcom,src-sel = <0>;
		status = "okay";
	};

	gpio@c400 { /* GPIO 5 */
		qcom,mode = <0>;
		qcom,pull = <0>;
		qcom,vin-sel = <2>;
		qcom,src-sel = <0>;
		status = "okay";
	};

	gpio@cc00 { /* GPIO 13 - HPH_EN0 */
		qcom,mode = <1>;
		qcom,output-type = <0>;
		qcom,pull = <5>;
		qcom,vin-sel = <2>;
		qcom,out-strength = <1>;
		qcom,src-sel = <2>;
		qcom,master-en = <1>;
		status = "okay";
	};

	gpio@ce00 { /* GPIO 15 */
		qcom,mode = <1>;
		qcom,output-type = <0>;
		qcom,pull = <5>;
		qcom,vin-sel = <2>;
		qcom,out-strength = <1>;
		qcom,src-sel = <2>;
		qcom,master-en = <1>;
		status = "okay";
	};

	gpio@d100 { /* GPIO 18 - Rome Sleep Clock */
		qcom,mode = <1>;		/* Digital output */
		qcom,output-type = <0>;		/* CMOS logic */
		qcom,invert = <0>;		/* Output low initially */
		qcom,vin-sel = <2>;		/* VIN 2 */
		qcom,src-sel = <3>;		/* Function 2 */
		qcom,out-strength = <2>;	/* Medium */
		qcom,master-en = <1>;		/* Enable GPIO */
		status = "okay";
	};

	gpio@d200 { /* GPIO 19 - Rome BT Reset */
		qcom,mode = <1>;		/* Digital output*/
		qcom,pull = <4>;		/* Pulldown 10uA */
		qcom,vin-sel = <2>;		/* VIN2 */
		qcom,src-sel = <0>;		/* GPIO */
		qcom,invert = <0>;		/* Invert */
		qcom,master-en = <1>;		/* Enable GPIO */
		status = "okay";
	};
};

&pmi8994_haptics {
	status = "okay";
};

&flash_led {
	qcom,follow-otst2-rb-disabled;
};

&blsp1_uart2 {
	status = "ok";
};

&i2c_6 {
	at24@51 {
		compatible = "atmel,24c32";
		reg = <0x51>;
	};
};

&i2c_7 {
	silabs4705@11 { /* SiLabs FM chip, slave id 0x11*/
		status = "ok";
		compatible = "silabs,si4705";
		reg = <0x11>;
		vdd-supply = <&pm8994_s4>;
		silabs,vdd-supply-voltage = <1800000 1800000>;
		va-supply = <&rome_vreg>;
		silabs,va-supply-voltage = <3300000 3300000>;
		pinctrl-names = "pmx_fm_active","pmx_fm_suspend";
		pinctrl-0 = <&fm_int_active &fm_status_int_active &fm_rst_active>;
		pinctrl-1 = <&fm_int_suspend &fm_status_int_suspend &fm_rst_suspend>;
		silabs,reset-gpio = <&tlmm 39 0>;
		silabs,int-gpio = <&tlmm 38 0>;
		silabs,status-gpio = <&tlmm 78 0>;
		#address-cells = <0>;
		interrupts = <0 1>;
		#interrupt-cells = <1>;
		interrupt-map-mask = <0xffffffff>;
		interrupt-map = <
				  0 &tlmm 38 2
				  1 &tlmm 78 1
				>;
		interrupt-names = "silabs_fm_int", "silabs_fm_status_int";
	};
};

&i2c_8 { /* BLSP2 QUP2 */
	nq@28 {
		compatible = "qcom,nq-nci";
		reg = <0x28>;
		qcom,nq-irq = <&tlmm 9 0x00>;
		qcom,nq-ven = <&tlmm 12 0x00>;
		qcom,nq-firm = <&pm8994_gpios 7 0x00>;
		qcom,nq-clkreq = <&pm8994_gpios 10 0x00>;
		qcom,nq-esepwr = <&pm8994_gpios 12 0x00>;
		interrupt-parent = <&tlmm>;
		qcom,clk-src = "BBCLK2";
		interrupts = <9 0>;
		interrupt-names = "nfc_irq";
		pinctrl-names = "nfc_active", "nfc_suspend";
		pinctrl-0 = <&nfc_int_active &nfc_disable_active>;
		pinctrl-1 = <&nfc_int_suspend &nfc_disable_suspend>;
		clocks = <&clock_gcc clk_bb_clk2_pin>;
		clock-names = "ref_clk";
	};
};

&i2c_9 {
	max98927@39 {/* max98927 smartpa device*/
		compatible = "maxim,max98927L";
		reg = <0x39>;
		mono_stereo_mode = <1>;
		interleave_mode = <0>;
		vmon-l-slot = <1>;
		imon-l-slot = <1>;
		vmon-r-slot = <1>;
		imon-r-slot = <1>;
		maxim,98927-reset-gpio = <&tlmm 90 0>;
	};

	max98927@3a {
		compatible = "maxim,max98927R";
		reg = <0x3a>;
		mono_stereo_mode = <1>;
		interleave_mode = <0>;
		vmon-l-slot = <1>;
		imon-l-slot = <1>;
		vmon-r-slot = <1>;
		imon-r-slot = <1>;
		maxim,98927-reset-gpio = <&tlmm 90 0>;
	};
};

&wil6210 {
	status = "ok";
};
